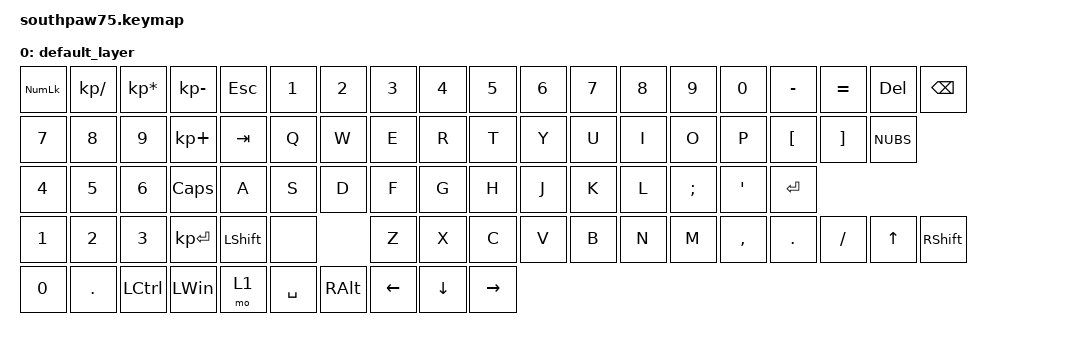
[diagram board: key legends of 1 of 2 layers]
/*
 * Copyright (c) 2020 The ZMK Contributors
 *
 * SPDX-License-Identifier: MIT
 */

#include <behaviors.dtsi>
#include <dt-bindings/zmk/bt.h>
#include <dt-bindings/zmk/keys.h>

/ {
    keymap {
        compatible = "zmk,keymap";

        default_layer {
            // ------------------------------------------------------------------------------------------------------------------
            // | NUM |  /  |  *  |  -  | ESC |  1  |  2  |  3  |  4  |  5  |  6  |  7  |  8  |  9  |  0  |  -  |  =  | DEL | BKSP |
            // |  7  |  8  |  9  |  +  | TAB  |  Q  |  W  |  E  |  R  |  T  |  Y  |  U  |  I  |  O  |  P  |  [  |  ]  |    \    |
            // |  4  |  5  |  6  |     | CAPS  |  A  |  S  |  D  |  F  |  G  |  H  |  J  |  K  |  L  |  ;  |  '  |     ENTER    |
            // |  1  |  2  |  3  | ENT |  SHIFT  |  Z  |  X  |  C  |  V  |  B  |  N  |  M  |  ,  |  .  |  /  |  SHIFT   | MO(2) |
            // |     0     |  .  |     |  CTL  |  WIN  |  ALT  |             SPACE              |  ALT  | MO(1) |  WIN  | CTRL  |
            // ------------------------------------------------------------------------------------------------------------------

            bindings = <
&kp KP_NLCK  &kp KP_DIVIDE  &kp KP_MULTIPLY  &kp KP_MINUS  &kp ESC    &kp N1     &kp N2         &kp N3          &kp N4          &kp N5           &kp N6  &kp N7  &kp N8  &kp N9    &kp N0     &kp MINUS  &kp EQUAL  &kp DEL       &kp BSPC
&kp N7       &kp N8         &kp N9           &kp KP_PLUS   &kp TAB    &kp Q      &kp W          &kp E           &kp R           &kp T            &kp Y   &kp U   &kp I   &kp O     &kp P      &kp LBKT   &kp RBKT   &kp NUBS
&kp N4       &kp N5         &kp N6           &kp CLCK      &kp A      &kp S      &kp D          &kp F           &kp G           &kp H            &kp J   &kp K   &kp L   &kp SEMI  &kp SQT    &kp RET
&kp N1       &kp N2         &kp N3           &kp KP_ENTER  &kp LSHFT  &none                     &kp Z           &kp X           &kp C            &kp V   &kp B   &kp N   &kp M     &kp COMMA  &kp DOT    &kp FSLH   &kp UP_ARROW  &kp RIGHT_SHIFT
&kp N0       &kp DOT        &kp LCTRL        &kp LWIN      &mo 1      &kp SPACE  &kp RIGHT_ALT  &kp LEFT_ARROW  &kp DOWN_ARROW  &kp RIGHT_ARROW
            >;
        };

        fn_layer {
            bindings = <
&bt BT_CLR    &trans        &trans        &bt BT_CLR  &kp GRAVE  &kp F1  &kp F2  &kp F3  &kp F4  &kp F5  &kp F6  &kp F7  &kp F8  &kp F9  &kp F10  &kp F11  &kp F12  &kp F13     &bootloader
&trans        &trans        &trans        &trans      &trans     &none   &none   &none   &none   &none   &none   &none   &none   &none   &none    &none    &none    &sys_reset
&bt BT_SEL 3  &bt BT_SEL 4  &trans        &trans      &trans     &none   &none   &none   &none   &none   &none   &none   &none   &none   &none    &none
&bt BT_SEL 0  &bt BT_SEL 1  &bt BT_SEL 2  &trans      &trans     &trans          &trans  &none   &none   &none   &none   &none   &none   &none    &none    &none    &none       &trans
&trans        &trans        &trans        &trans      &trans     &trans  &trans  &trans  &trans
            >;
        };
    };
};
